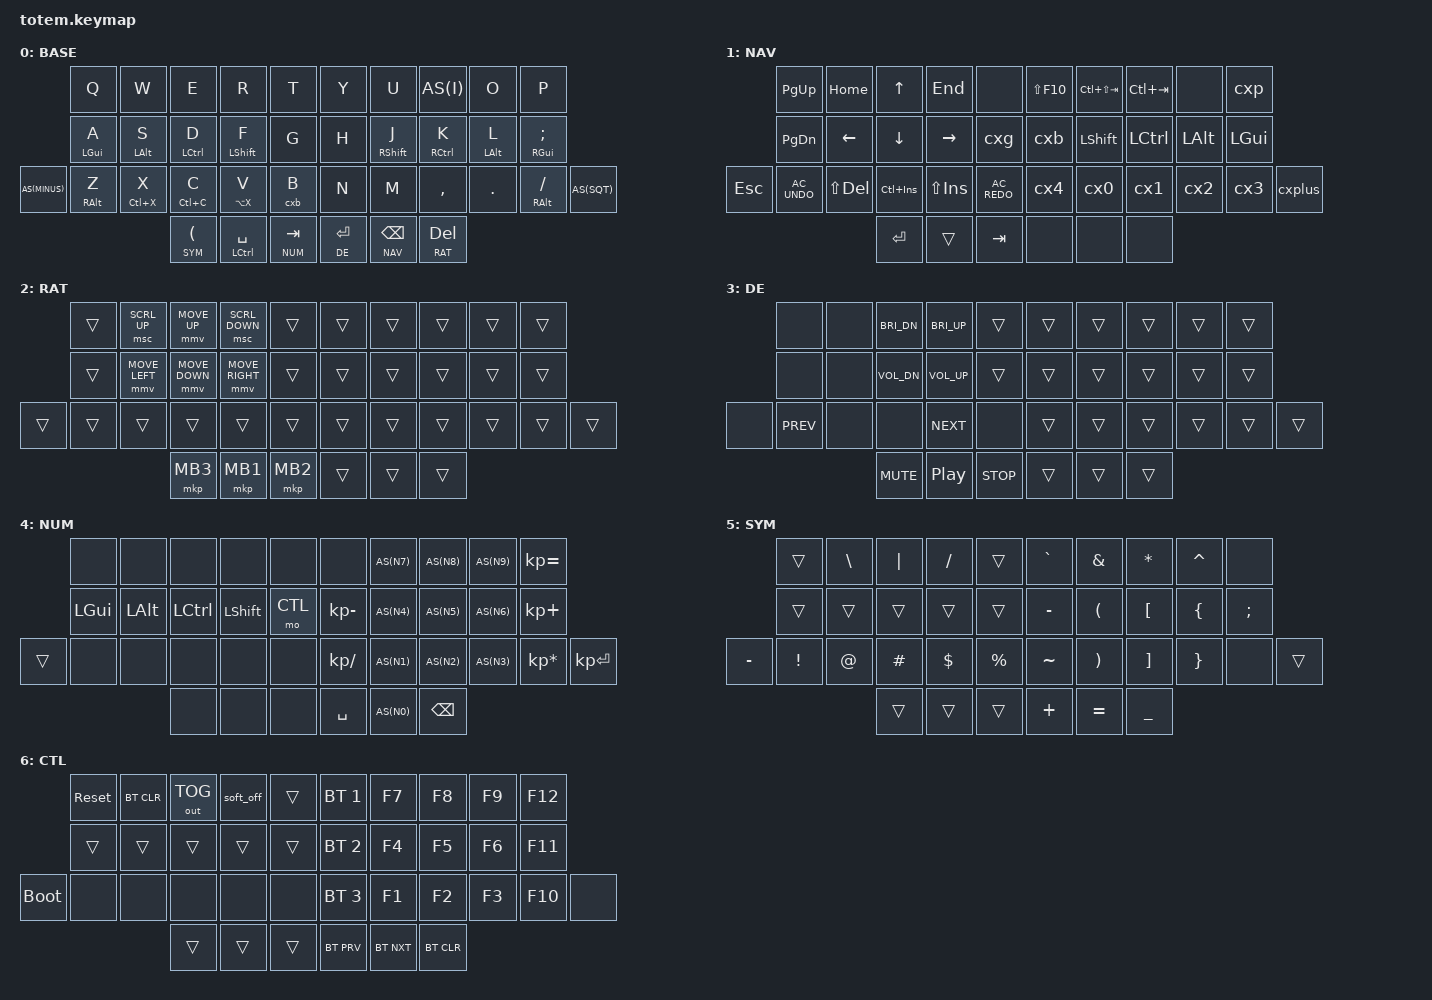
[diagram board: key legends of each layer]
#include <behaviors.dtsi>
#include <dt-bindings/zmk/keys.h>
#include <dt-bindings/zmk/bt.h>
#include <dt-bindings/zmk/outputs.h>

// Mouse keys
#define ZMK_POINTING_DEFAULT_MOVE_VAL 1500  // default: 600
#define ZMK_POINTING_DEFAULT_SCRL_VAL 20    // default: 10
#include <dt-bindings/zmk/pointing.h>

#define BASE 0
#define NAV  1
#define RAT  2
#define DE   3
#define NUM  4
#define SYM  5
#define CTL  6

#define AS(keycode) &as LS(keycode) keycode // Autoshift

#define COPY  &kp LC(INS)
#define PASTE &kp LS(INS)
#define CUT   &kp LS(DEL)
#define UNDO  &kp C_AC_UNDO
#define REDO  &kp C_AC_REDO

/* TODO Add french and portuguese diactricts */

// require-prior-idle-ms = <80>;
&mt {
    flavor = "tap-preferred"; // try balanced flavour
    tapping-term-ms = <200>;
    quick-tap-ms = <150>;
};

&lt { quick-tap-ms = <150>; };

/ {
    behaviors {
        sbt: switch_buffer_tap {
            compatible = "zmk,behavior-hold-tap";
            #binding-cells = <2>;
            tapping-term-ms = <200>;
            quick-tap-ms = <0>;
            flavor = "tap-preferred";
            bindings = <&cxb>, <&kp>;
        };
        as: auto_shift {
            compatible = "zmk,behavior-hold-tap";
            #binding-cells = <2>;
            tapping-term-ms = <200>;
            quick-tap-ms = <0>; // TODO repeats anyway, why?
            flavor = "tap-preferred";
            bindings = <&kp>, <&kp>;
        };
    };
    combos {
        compatible = "zmk,combos";
        combo_esc {
            timeout-ms = <50>;
            key-positions = <0 1>;
            bindings = <&kp ESC>;
        };
        caps {
            timeout-ms = <50>;
            key-positions = <13 16>;
            bindings = <&caps_word>;
        };
    };
    macros {
        cx0: cx0 {
            compatible = "zmk,behavior-macro";
            #binding-cells = <0>;
            bindings = <&kp LC(X) &kp N0>;
        };
        cx1: cx1 {
            compatible = "zmk,behavior-macro";
            #binding-cells = <0>;
            bindings = <&kp LC(X) &kp N1>;
        };
        cx2: cx2 {
            compatible = "zmk,behavior-macro";
            #binding-cells = <0>;
            bindings = <&kp LC(X) &kp N2>;
        };
        cx3: cx3 {
            compatible = "zmk,behavior-macro";
            #binding-cells = <0>;
            bindings = <&kp LC(X) &kp N3>;
        };
        cx4: cx4 {
            compatible = "zmk,behavior-macro";
            #binding-cells = <0>;
            bindings = <&kp LC(X) &kp N4>;
        };
        cxp: cxp {
            compatible = "zmk,behavior-macro";
            #binding-cells = <0>;
            bindings = <&kp LC(X) &kp P>;
        };
        cxg: cxg {
            compatible = "zmk,behavior-macro";
            #binding-cells = <0>;
            bindings = <&kp LC(X) &kp G>;
        };
        cxb: cxb {
            compatible = "zmk,behavior-macro";
            #binding-cells = <0>;
            bindings = <&kp LC(X) &kp B>;
        };
        cxplus: cxplus {
            compatible = "zmk,behavior-macro";
            #binding-cells = <0>;
            bindings = <&kp LC(X) &kp PLUS>;
        };
        gif: gif {
            compatible = "zmk,behavior-macro";
            #binding-cells = <0>;
            bindings
            = <&macro_press &kp LSHFT>
            , <&macro_tap &kp N2>
            , <&macro_release &kp LSHFT>
            , <&macro_tap &kp G &kp I &kp F>
            ;
        };
    };
    keymap {
        compatible = "zmk,keymap";
        base_layer {
            label= "BASE";
            bindings = <
// ╷           ╷           ╷           ╷           ╷           ╷           ╷   ╷           ╷           ╷           ╷           ╷           ╷           ╷
                &kp Q       &kp W       &kp E       &kp R       &kp T           &kp Y       &kp U       AS(I)       &kp O       &kp P
                &mt LGUI A  &mt LALT S  &mt LCTRL D &mt LSHFT F &kp G           &kp H       &mt RSHFT J &mt RCTRL K &mt LALT L  &mt RGUI SEMI
    AS(MINUS)   &mt RALT Z  &mt LC(X) X &mt LC(C) C &mt LA(X) V &sbt 0 B        &kp N       &kp M       &kp COMMA   &kp DOT     &mt RALT FSLH AS(SQT)
                                        &lt SYM LPAR &mt LCTRL SPACE &lt NUM TAB &lt DE RET &lt NAV BSPC &lt RAT DEL
            >;
        };
        nav_layer {
            label= "NAV";
            bindings = <
// ╷           ╷           ╷           ╷           ╷           ╷           ╷   ╷           ╷           ╷           ╷           ╷           ╷           ╷
                &kp PG_UP   &kp HOME    &kp UP      &kp END     &none           &kp LS(F10) &kp LC(LS(TAB)) &kp LC(TAB) &none   &cxp
                &kp PG_DN   &kp LEFT    &kp DOWN    &kp RIGHT   &cxg            &cxb        &kp LSHFT   &kp LCTRL   &kp LALT    &kp LGUI
    &kp ESC     UNDO        CUT         COPY        PASTE       REDO            &cx4        &cx0        &cx1        &cx2        &cx3        &cxplus
                                        &kp RET     &trans      &kp TAB         &none       &none       &none
            >;
        };
        rat_layer {
            label= "RAT";
            bindings = <
// ╷           ╷           ╷           ╷           ╷           ╷           ╷   ╷           ╷           ╷           ╷           ╷           ╷           ╷
                &trans      &msc SCRL_UP &mmv MOVE_UP &msc SCRL_DOWN &trans     &trans      &trans      &trans      &trans      &trans
                &trans      &mmv MOVE_LEFT &mmv MOVE_DOWN &mmv MOVE_RIGHT &trans &trans     &trans      &trans      &trans      &trans
    &trans      &trans      &trans      &trans      &trans      &trans          &trans      &trans      &trans      &trans      &trans      &trans
                                        &mkp MB3    &mkp MB1    &mkp MB2        &trans      &trans      &trans
            >;
        };
        de_layer {
            label= "DE";
            bindings = <
// ╷           ╷           ╷           ╷           ╷           ╷           ╷   ╷           ╷           ╷           ╷           ╷           ╷           ╷
                &none       &none       &kp C_BRI_DN &kp C_BRI_UP &trans        &trans      &trans      &trans      &trans      &trans
                &none       &none       &kp C_VOL_DN &kp C_VOL_UP &trans        &trans      &trans      &trans      &trans      &trans
    &none       &kp C_PREV  &none       &none       &kp C_NEXT  &none           &trans      &trans      &trans      &trans      &trans      &trans
                                        &kp C_MUTE  &kp C_PP    &kp C_STOP      &trans      &trans      &trans
            >;
        };
        num_layer {
            label= "NUM";
            /* think about space, return and backspace keys  */
            bindings = <
// ╷           ╷           ╷           ╷           ╷           ╷           ╷   ╷           ╷           ╷           ╷           ╷           ╷           ╷
                &none       &none       &none       &none       &none           &none       AS(N7)      AS(N8)      AS(N9)      &kp KP_EQUAL
                &kp LGUI    &kp LALT    &kp LCTRL   &kp LSHFT   &mo CTL         &kp KP_MINUS AS(N4)     AS(N5)      AS(N6)      &kp KP_PLUS
    &trans      &none       &none       &none       &none       &none           &kp KP_SLASH AS(N1)     AS(N2)      AS(N3)      &kp KP_MULTIPLY &kp KP_ENTER
                                        &none       &none       &none           &kp SPACE   AS(N0)      &kp BSPC
            >;
        };
        sym_layer {
            label= "SYM";
            bindings = <
// ╷           ╷           ╷           ╷           ╷           ╷           ╷   ╷           ╷           ╷           ╷           ╷           ╷           ╷
                &trans      &kp BSLH    &kp PIPE    &kp FSLH    &trans          &kp GRAVE   &kp AMPS    &kp STAR    &kp CARET   &none
                &trans      &trans      &trans      &trans      &trans          &kp MINUS   &kp LPAR    &kp LBKT    &kp LBRC    &kp SEMI
    &kp MINUS   &kp EXCL    &kp AT      &kp HASH    &kp DOLLAR  &kp PRCNT       &kp TILDE   &kp RPAR    &kp RBKT    &kp RBRC    &none    &trans
                                        &trans      &trans      &trans          &kp PLUS    &kp EQUAL   &kp UNDER
            >;
        };
        ctl_layer {
            label= "CTL";
            bindings = <
// ╷           ╷           ╷           ╷           ╷           ╷           ╷   ╷           ╷           ╷           ╷           ╷           ╷           ╷
                &sys_reset  &bt BT_CLR  &out OUT_TOG &soft_off  &trans          &bt BT_SEL 1 &kp F7      &kp F8      &kp F9      &kp F12
                &trans      &trans      &trans      &trans      &trans          &bt BT_SEL 2 &kp F4      &kp F5      &kp F6      &kp F11
    &bootloader &none       &none       &none       &none       &none           &bt BT_SEL 3 &kp F1      &kp F2      &kp F3      &kp F10     &none
                                        &trans      &trans      &trans          &bt BT_PRV   &bt BT_NXT  &bt BT_CLR
            >;
        };
    };
};
